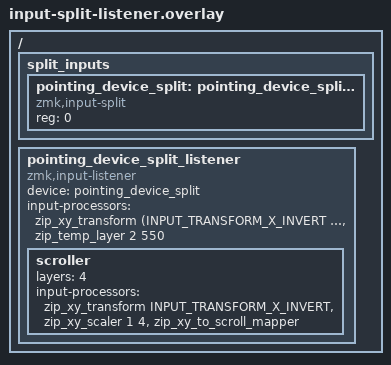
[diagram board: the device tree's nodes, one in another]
#include <input/processors.dtsi>
#include <dt-bindings/zmk/input_transform.h>

/{
    split_inputs {
        #address-cells = <1>;
        #size-cells = <0>;

        pointing_device_split: pointing_device_split@0 {
            compatible = "zmk,input-split";
            reg = <0>;
        };
    };

    pointing_device_split_listener: pointing_device_split_listener {
        compatible = "zmk,input-listener";
        device = <&pointing_device_split>;
        status = "okay";

        // Default: mouse movement mode
        input-processors = <
            &zip_xy_transform (INPUT_TRANSFORM_X_INVERT | INPUT_TRANSFORM_Y_INVERT)
            &zip_temp_layer 2 550
        >;

        // When layer 4 is active: scroll mode
        scroller {
            layers = <4>;
            input-processors = <
                &zip_xy_transform INPUT_TRANSFORM_X_INVERT
                &zip_xy_scaler 1 4
                &zip_xy_to_scroll_mapper
            >;
        };
     };
};
